# S6E2C4 register map
File version: 1.0
Registers are 32-bit, read-write, reset 0x0 unless marked. A register's access mark holds for its fields unless they carry their own. Offsets are from the block's base; [hi:lo] are bit positions.

## HDMICEC0 — HDMI-CEC ch.0
Base 0x40034000
Same registers: HDMICEC1 0x40034100
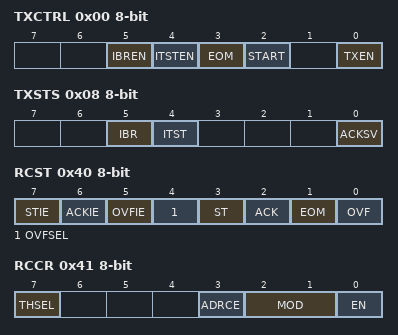
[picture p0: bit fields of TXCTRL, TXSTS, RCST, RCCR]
0x00 TXCTRL 8-bit — Transmission Control Register
  [5] IBREN — Bus error detection interrupt enable bit
  [4] ITSTEN — transmission status interrupt enable bit
  [3] EOM — EOM setting bit
  [2] START — START setting bit
  [0] TXEN — Transmission operation enable bit
0x04 TXDATA 8-bit — Transmission Data Register
  [7:0] TXDATA — Transmission Data
0x08 TXSTS 8-bit — Transmission Status Register
  [5] IBR — Bus error detection interrupt request bit
  [4] ITST — Transmission status interrupt request bit
  [0] ACKSV — ACK cycle value bit
0x0C SFREE 8-bit — Signal Free Time Setting Register
  [3:0] SFREE — Signal free time setting bits
0x40 RCST 8-bit — Reception Interrupt Control Register
  [7] STIE — Start bit interrupt enable bit
  [6] ACKIE — ACK interrupt enable bit
  [5] OVFIE — Counter overflow interrupt enable bit
  [4] OVFSEL — Counter overflow detection condition setting bit
  [3] ST — Start bit detection bit
  [2] ACK — ACK: ACK detection bit
  [1] EOM — EOM detection bit
  [0] OVF — Counter overflow detection bit
0x41 RCCR 8-bit — Reception Control Register
  [7] THSEL — Threshold selection bit
  [3] ADRCE — Address comparison enable bit
  [2:1] MOD — Operation mode setting bits
  [0] EN — Operation enable bit
0x44 RCDAHW 8-bit — "H" Width Setting Register A
  [7:0] RCDAHW — "H" Width Setting A
0x45 RCSHW 8-bit — Start Bit "H" Width Setting Register
  [7:0] RCSHW — Start Bit "H" Width Setting
0x49 RCDBHW 8-bit — "H" Width Setting Register B
  [7:0] RCDBHW — "H" Width Setting B
0x4C RCADR2 8-bit — Device Address Setting Register 2
  [4:0] RCADR2 — Device Address 2
0x4D RCADR1 8-bit — Device Address Setting Register 1
  [4:0] RCADR1 — Device Address 1
0x50 RCDTHL 8-bit ro — Data Save Register (High-Low)
0x51 RCDTHH 8-bit ro — Data Save Register (High-High)
0x54 RCDTLL 8-bit ro — Data Save Register (Low-Low)
0x55 RCDTLH 8-bit ro — Data Save Register (Low-High)
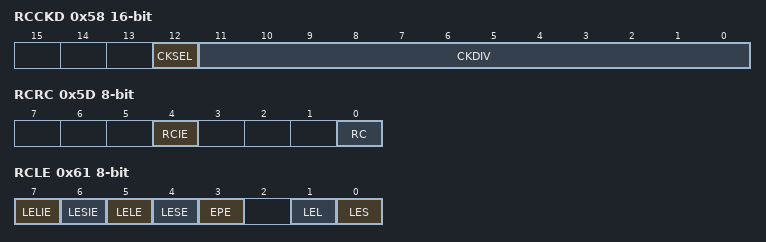
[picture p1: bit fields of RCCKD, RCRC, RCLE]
0x58 RCCKD 16-bit — Clock Division Setting Register
  [12] CKSEL — Operating clock selection bit
  [11:0] CKDIV — Operating clock division setting bits
0x5C RCRHW 8-bit — Repeat Code "H" Width Setting Register
  [7:0] RCRHW — "Repeat code "H" width setting bits"
0x5D RCRC 8-bit — Repeat Code Interrupt Control Register
  [4] RCIE — Repeat Code Interrupt enable bit
  [0] RC — Repeat code detection flag bit
0x61 RCLE 8-bit — Data Bit Width Violation Control Register
  [7] LELIE — Maximum data bit width violation interrupt enable bit
  [6] LESIE — Minimum data bit width violation interrupt enable bit
  [5] LELE — Maximum data bit width violation detection enable bit
  [4] LESE — Minimum data bit width violation detection enable bit
  [3] EPE — Error pulse output enable bit
  [1] LEL — Maximum data bit width violation detection flag bit
  [0] LES — Minimum data bit width violation detection flag bit
0x64 RCLESW 8-bit — Minimum Data Bit Width Setting Register
  [7:0] RCLESW — Minimum data bit width setting bits
0x65 RCLELW 8-bit — Maximum Data Bit Width Setting Register
  [7:0] RCLELW — Maximum data bit width setting bits

## LVD — Low-voltage Detection
Base 0x40035000
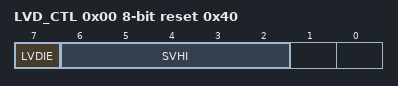
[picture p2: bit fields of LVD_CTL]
0x00 LVD_CTL 8-bit reset 0x40 — Low-voltage Detection Voltage Control Register
  [7] LVDIE — Low-voltage detection interrupt enable bit
  [6:2] SVHI — Low-voltage detection interrupt voltage setting bits
0x04 LVD_STR 8-bit ro — Low-voltage Detection Interrupt Factor Register
  [7] LVDIR — Low-voltage detection interrupt factor bit
0x08 LVD_CLR 8-bit reset 0x80 — Low-voltage Detection Interrupt Factor Clear Register
  [7] LVDCL — Low-voltage detection interrupt factor clear bit
0x0C LVD_RLR reset 0x1 — Low-voltage Detection Voltage Protection Register
  [31:0] LVDLCK — Low-voltage Detection Voltage Control Register protection bits
0x10 LVD_STR2 8-bit ro reset 0x40 — Low-voltage Detection Circuit Status Register
  [7] LVDIRDY — Low-voltage detection interrupt status flag
